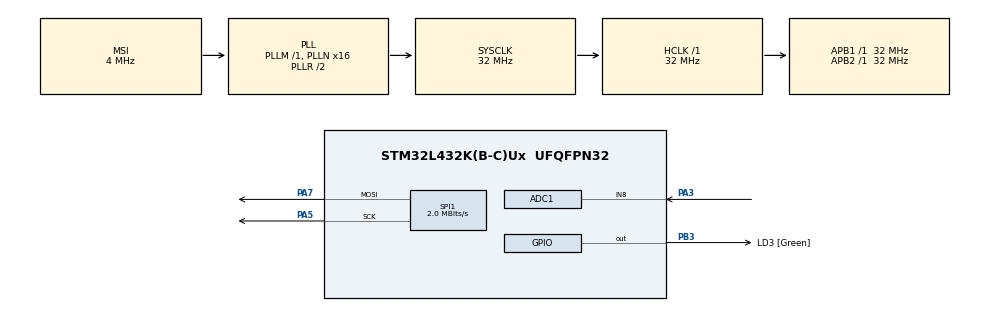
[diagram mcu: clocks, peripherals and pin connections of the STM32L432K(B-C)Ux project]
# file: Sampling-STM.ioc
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ADC1.Channel-0\#ChannelRegularConversion=ADC_CHANNEL_8
ADC1.DMAContinuousRequests=ENABLE
ADC1.ExternalTrigConv=ADC_EXTERNALTRIG_T1_TRGO
ADC1.ExternalTrigConvEdge=ADC_EXTERNALTRIGCONVEDGE_RISINGFALLING
ADC1.NbrOfConversionFlag=1
ADC1.OffsetNumber-0\#ChannelRegularConversion=ADC_OFFSET_NONE
ADC1.Rank-0\#ChannelRegularConversion=1
ADC1.SamplingTime-0\#ChannelRegularConversion=ADC_SAMPLETIME_2CYCLES_5
ADC1.master=1
Dma.ADC1.0.Direction=DMA_PERIPH_TO_MEMORY
Dma.ADC1.0.Instance=DMA1_Channel1
Dma.ADC1.0.MemDataAlignment=DMA_MDATAALIGN_HALFWORD
Dma.ADC1.0.MemInc=DMA_MINC_ENABLE
Dma.ADC1.0.Mode=DMA_CIRCULAR
Dma.ADC1.0.PeriphDataAlignment=DMA_PDATAALIGN_HALFWORD
Dma.ADC1.0.PeriphInc=DMA_PINC_DISABLE
Dma.ADC1.0.Priority=DMA_PRIORITY_LOW
Dma.Request0=ADC1
Mcu.Family=STM32L4
Mcu.Name=STM32L432K(B-C)Ux
Mcu.Package=UFQFPN32
NVIC.DMA1_Channel1_IRQn=true\:0\:0\:false\:false\:true\:false\:true\:true
NVIC.PriorityGroup=NVIC_PRIORITYGROUP_4
NVIC.SPI1_IRQn=true\:0\:0\:false\:false\:true\:true\:true\:true
PA0.GPIO_Label=MCO [High speed clock in]
PA0.Mode=HSE-External-Clock-Source-for-LittleOrca
PA0.Signal=RCC_CK_IN
PA13\ (JTMS-SWDIO).GPIO_Label=SWDIO
PA13\ (JTMS-SWDIO).Mode=Serial_Wire
PA13\ (JTMS-SWDIO).Signal=SYS_JTMS-SWDIO
PA14\ (JTCK-SWCLK).GPIO_Label=SWCLK
PA14\ (JTCK-SWCLK).Mode=Serial_Wire
PA14\ (JTCK-SWCLK).Signal=SYS_JTCK-SWCLK
PA3.Signal=ADCx_IN8
PA5.GPIO_Speed=GPIO_SPEED_FREQ_VERY_HIGH
PA5.Mode=TX_Only_Simplex_Unidirect_Master
PA5.Signal=SPI1_SCK
PA7.GPIO_Speed=GPIO_SPEED_FREQ_VERY_HIGH
PA7.Mode=TX_Only_Simplex_Unidirect_Master
PA7.Signal=SPI1_MOSI
PB3\ (JTDO-TRACESWO).GPIO_Label=LD3 [Green]
PB3\ (JTDO-TRACESWO).Signal=GPIO_Output
PC14-OSC32_IN\ (PC14).Mode=LSE-External-Oscillator
PC14-OSC32_IN\ (PC14).Signal=RCC_OSC32_IN
PC15-OSC32_OUT\ (PC15).Mode=LSE-External-Oscillator
PC15-OSC32_OUT\ (PC15).Signal=RCC_OSC32_OUT
ProjectManager.HeapSize=0x200
ProjectManager.StackSize=0x400
ProjectManager.TargetToolchain=STM32CubeIDE
RCC.ADCFreq_Value=32000000
RCC.AHBFreq_Value=32000000
RCC.APB1Freq_Value=32000000
RCC.APB1TimFreq_Value=32000000
RCC.APB2Freq_Value=32000000
RCC.APB2TimFreq_Value=32000000
RCC.CortexFreq_Value=32000000
RCC.HCLKFreq_Value=32000000
RCC.HSE_VALUE=8000000
RCC.HSI16_VALUE=16000000
RCC.HSI48_VALUE=48000000
RCC.HSI_VALUE=16000000
RCC.MSI_VALUE=4000000
RCC.PLLMUL=RCC_PLLMUL_4
RCC.PLLN=16
RCC.PLLSAI1N=16
RCC.SYSCLKFreq_VALUE=32000000
RCC.SYSCLKSource=RCC_SYSCLKSOURCE_PLLCLK
RCC.USBFreq_Value=32000000
RCC.VCOOutputFreq_Value=64000000
SH.ADCx_IN8.0=ADC1_IN8,IN8-Single-Ended
SPI1.BaudRatePrescaler=SPI_BAUDRATEPRESCALER_16
SPI1.CalculateBaudRate=2.0 MBits/s
SPI1.DataSize=SPI_DATASIZE_16BIT
SPI1.Direction=SPI_DIRECTION_2LINES
SPI1.FirstBit=SPI_FIRSTBIT_MSB
SPI1.Mode=SPI_MODE_MASTER
SPI1.VirtualType=VM_MASTER
TIM1.Period=1599
TIM1.TIM_MasterOutputTrigger=TIM_TRGO_UPDATE
VP_TIM1_VS_ClockSourceINT.Mode=Internal
board=NUCLEO-L432KC

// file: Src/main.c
/* USER CODE BEGIN Header */
/**
  ******************************************************************************
  * @file           : main.c
  * @brief          : Main program body
  ******************************************************************************
  * @attention
  *
  * Copyright (c) 2025 STMicroelectronics.
  * All rights reserved.
  *
  * This software is licensed under terms that can be found in the LICENSE file
  * in the root directory of this software component.
  * If no LICENSE file comes with this software, it is provided AS-IS.
  *
  ******************************************************************************
  */
/* USER CODE END Header */
#include "main.h"
#include "adc.h"
#include "dma.h"
#include "spi.h"
#include "tim.h"
#include "gpio.h"

/* USER CODE BEGIN Includes */
#include <string.h>

#include "spi.h"
/* USER CODE END Includes */

/* USER CODE BEGIN PD */
#define SAMPLES 1000
/* USER CODE END PD */

/* USER CODE BEGIN PV */
volatile uint16_t dma_buffer[SAMPLES];
/* USER CODE END PV */

void SystemClock_Config(void);

int main(void)
{

  /* MCU Configuration--------------------------------------------------------*/

  /* Reset of all peripherals, Initializes the Flash interface and the Systick. */
  HAL_Init();

  /* Configure the system clock */
  SystemClock_Config();

  /* Initialize all configured peripherals */
  MX_GPIO_Init();
  MX_DMA_Init();
  MX_ADC1_Init();
  MX_SPI1_Init();
  MX_TIM1_Init();
  /* USER CODE BEGIN 2 */

  HAL_ADCEx_Calibration_Start(&hadc1, ADC_SINGLE_ENDED);
  //HAL_Delay(10);
  HAL_TIM_Base_Start(&htim1);

  // Start ADC conversion
  HAL_ADC_Start_DMA(&hadc1, (uint32_t*)dma_buffer, SAMPLES);

  /* USER CODE END 2 */

  /* Infinite loop */
  while (1)
  {

  }
}

void SystemClock_Config(void)
{
  RCC_OscInitTypeDef RCC_OscInitStruct = {0};
  RCC_ClkInitTypeDef RCC_ClkInitStruct = {0};

  /** Configure the main internal regulator output voltage
  */
  if (HAL_PWREx_ControlVoltageScaling(PWR_REGULATOR_VOLTAGE_SCALE1) != HAL_OK)
  {
    Error_Handler();
  }

  /** Configure LSE Drive Capability
  */
  HAL_PWR_EnableBkUpAccess();
  __HAL_RCC_LSEDRIVE_CONFIG(RCC_LSEDRIVE_LOW);

  /** Initializes the RCC Oscillators according to the specified parameters
  * in the RCC_OscInitTypeDef structure.
  */
  RCC_OscInitStruct.OscillatorType = RCC_OSCILLATORTYPE_LSE|RCC_OSCILLATORTYPE_MSI;
  RCC_OscInitStruct.LSEState = RCC_LSE_ON;
  RCC_OscInitStruct.MSIState = RCC_MSI_ON;
  RCC_OscInitStruct.MSICalibrationValue = 0;
  RCC_OscInitStruct.MSIClockRange = RCC_MSIRANGE_6;
  RCC_OscInitStruct.PLL.PLLState = RCC_PLL_ON;
  RCC_OscInitStruct.PLL.PLLSource = RCC_PLLSOURCE_MSI;
  RCC_OscInitStruct.PLL.PLLM = 1;
  RCC_OscInitStruct.PLL.PLLN = 16;
  RCC_OscInitStruct.PLL.PLLP = RCC_PLLP_DIV7;
  RCC_OscInitStruct.PLL.PLLQ = RCC_PLLQ_DIV2;
  RCC_OscInitStruct.PLL.PLLR = RCC_PLLR_DIV2;
  if (HAL_RCC_OscConfig(&RCC_OscInitStruct) != HAL_OK)
  {
    Error_Handler();
  }

  /** Initializes the CPU, AHB and APB buses clocks
  */
  RCC_ClkInitStruct.ClockType = RCC_CLOCKTYPE_HCLK|RCC_CLOCKTYPE_SYSCLK
                              |RCC_CLOCKTYPE_PCLK1|RCC_CLOCKTYPE_PCLK2;
  RCC_ClkInitStruct.SYSCLKSource = RCC_SYSCLKSOURCE_PLLCLK;
  RCC_ClkInitStruct.AHBCLKDivider = RCC_SYSCLK_DIV1;
  RCC_ClkInitStruct.APB1CLKDivider = RCC_HCLK_DIV1;
  RCC_ClkInitStruct.APB2CLKDivider = RCC_HCLK_DIV1;

  if (HAL_RCC_ClockConfig(&RCC_ClkInitStruct, FLASH_LATENCY_1) != HAL_OK)
  {
    Error_Handler();
  }

  /** Enable MSI Auto calibration
  */
  HAL_RCCEx_EnableMSIPLLMode();
}

/* USER CODE BEGIN 4 */

void HAL_ADC_ConvCpltCallback(ADC_HandleTypeDef* hadc)
{

  // Next round
  //HAL_ADC_Start_DMA(&hadc1, (uint32_t*)dma_buffer, SAMPLES);

  // Interrupt occurs when transfer and conversion is complete
  HAL_SPI_Transmit_IT(&hspi1, (uint8_t*)&dma_buffer[SAMPLES / 2], (SAMPLES/2) * 2);

}

void HAL_ADC_ConvHalfCpltCallback(ADC_HandleTypeDef* hadc)
{
  // Interrupt occurs on half of the buffer has been filled

  HAL_SPI_Transmit_IT(&hspi1, (uint8_t*)&dma_buffer[0], (SAMPLES/2) * 2);
}

/* USER CODE END 4 */

void Error_Handler(void)
{
  __disable_irq();
  while (1)
  {
  }
}
